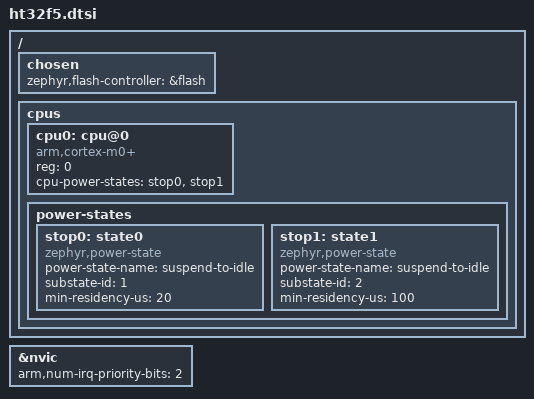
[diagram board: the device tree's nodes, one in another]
/*
 * Copyright (c) 2025 Alex Fabre <alex.fabre@rtone.fr>
 *
 * SPDX-License-Identifier: Apache-2.0
 */

#include <arm/armv6-m.dtsi>
#include <zephyr/dt-bindings/gpio/gpio.h>
#include <zephyr/dt-bindings/i2c/i2c.h>
#include <zephyr/dt-bindings/pwm/pwm.h>
#include <zephyr/dt-bindings/adc/adc.h>
#include <freq.h>

/ {
	chosen {
		zephyr,flash-controller = &flash;
	};

	cpus {
		#address-cells = <1>;
		#size-cells = <0>;

		cpu0: cpu@0 {
			device_type = "cpu";
			compatible = "arm,cortex-m0+";
			reg = <0>;
			cpu-power-states = <&stop0 &stop1>;
		};

		power-states {
			stop0: state0 {
				compatible = "zephyr,power-state";
				power-state-name = "suspend-to-idle";
				substate-id = <1>;
				min-residency-us = <20>;
			};

			stop1: state1 {
				compatible = "zephyr,power-state";
				power-state-name = "suspend-to-idle";
				substate-id = <2>;
				min-residency-us = <100>;
			};
		};
	};

	/* SRAM defined in SoC-specific dtsi files */
};

&nvic {
	arm,num-irq-priority-bits = <2>;
};
